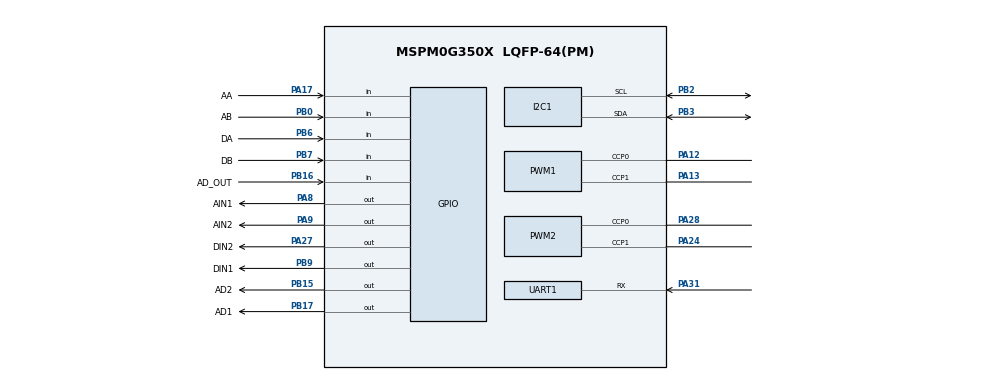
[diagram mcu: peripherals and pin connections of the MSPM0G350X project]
/**
 * @cliArgs --device "MSPM0G350X" --part "Default" --package "LQFP-64(PM)" --product "mspm0_sdk@2.10.00.04"
 * @versions {"tool":"1.26.2+4477"}
 */

/**
 * Import the modules used in this configuration.
 */
const GPIO    = scripting.addModule("/ti/driverlib/GPIO", {}, false);
const GPIO1   = GPIO.addInstance();
const GPIO2   = GPIO.addInstance();
const GPIO3   = GPIO.addInstance();
const GPIO4   = GPIO.addInstance();
const I2C     = scripting.addModule("/ti/driverlib/I2C", {}, false);
const I2C1    = I2C.addInstance();
const PWM     = scripting.addModule("/ti/driverlib/PWM", {}, false);
const PWM1    = PWM.addInstance();
const PWM2    = PWM.addInstance();
const SYSCTL  = scripting.addModule("/ti/driverlib/SYSCTL");
const SYSTICK = scripting.addModule("/ti/driverlib/SYSTICK");
const TIMER   = scripting.addModule("/ti/driverlib/TIMER", {}, false);
const TIMER1  = TIMER.addInstance();
const TIMER2  = TIMER.addInstance();
const UART    = scripting.addModule("/ti/driverlib/UART", {}, false);
const UART1   = UART.addInstance();

/**
 * Write custom configuration values to the imported modules.
 */
GPIO1.$name                         = "GPIO_MOTOR";
GPIO1.associatedPins.create(8);
GPIO1.associatedPins[0].$name       = "AIN1";
GPIO1.associatedPins[0].pin.$assign = "PA8";
GPIO1.associatedPins[1].$name       = "AIN2";
GPIO1.associatedPins[1].pin.$assign = "PA9";
GPIO1.associatedPins[2].$name       = "DIN1";
GPIO1.associatedPins[2].pin.$assign = "PB9";
GPIO1.associatedPins[3].$name       = "DIN2";
GPIO1.associatedPins[3].pin.$assign = "PA27";
GPIO1.associatedPins[4].$name       = "AA";
GPIO1.associatedPins[4].direction   = "INPUT";
GPIO1.associatedPins[4].interruptEn = true;
GPIO1.associatedPins[4].polarity    = "RISE";
GPIO1.associatedPins[4].pin.$assign = "PA17";
GPIO1.associatedPins[5].$name       = "AB";
GPIO1.associatedPins[5].direction   = "INPUT";
GPIO1.associatedPins[5].pin.$assign = "PB0";
GPIO1.associatedPins[6].$name       = "DA";
GPIO1.associatedPins[6].direction   = "INPUT";
GPIO1.associatedPins[6].interruptEn = true;
GPIO1.associatedPins[6].polarity    = "RISE";
GPIO1.associatedPins[6].pin.$assign = "PB6";
GPIO1.associatedPins[7].$name       = "DB";
GPIO1.associatedPins[7].direction   = "INPUT";
GPIO1.associatedPins[7].pin.$assign = "PB7";

const Board = scripting.addModule("/ti/driverlib/Board", {}, false);

GPIO2.$name                         = "TRACT";
GPIO2.associatedPins.create(4);
GPIO2.associatedPins[0].$name       = "AD0";
GPIO2.associatedPins[1].$name       = "AD1";
GPIO2.associatedPins[1].pin.$assign = "PB17";
GPIO2.associatedPins[2].$name       = "AD2";
GPIO2.associatedPins[2].pin.$assign = "PB15";
GPIO2.associatedPins[3].$name       = "AD_OUT";
GPIO2.associatedPins[3].direction   = "INPUT";
GPIO2.associatedPins[3].pin.$assign = "PB16";

GPIO3.$name                              = "USER_SWITCHES_PA18";
GPIO3.associatedPins[0].direction        = "INPUT";
GPIO3.associatedPins[0].internalResistor = "PULL_UP";
GPIO3.associatedPins[0].assignedPort     = "PORTA";
GPIO3.associatedPins[0].assignedPin      = "18";
GPIO3.associatedPins[0].$name            = "USER_SWITCH_PA18";

GPIO4.$name                          = "GPIO_SWITCHES_PB21";
GPIO4.associatedPins[0].direction    = "INPUT";
GPIO4.associatedPins[0].$name        = "USER_SWITCH_1";
GPIO4.associatedPins[0].assignedPort = "PORTB";
GPIO4.associatedPins[0].assignedPin  = "21";

I2C1.$name                             = "OLED";
I2C1.basicEnableController             = true;
I2C1.basicControllerStandardBusSpeed   = "Fast";
I2C1.peripheral.sdaPin.$assign         = "PB3";
I2C1.peripheral.sclPin.$assign         = "PB2";
I2C1.sdaPinConfig.hideOutputInversion  = scripting.forceWrite(false);
I2C1.sdaPinConfig.onlyInternalResistor = scripting.forceWrite(false);
I2C1.sdaPinConfig.passedPeripheralType = scripting.forceWrite("Digital");
I2C1.sdaPinConfig.$name                = "ti_driverlib_gpio_GPIOPinGeneric2";
I2C1.sdaPinConfig.enableConfig         = true;
I2C1.sdaPinConfig.internalResistor     = "PULL_UP";
I2C1.sclPinConfig.hideOutputInversion  = scripting.forceWrite(false);
I2C1.sclPinConfig.onlyInternalResistor = scripting.forceWrite(false);
I2C1.sclPinConfig.passedPeripheralType = scripting.forceWrite("Digital");
I2C1.sclPinConfig.$name                = "ti_driverlib_gpio_GPIOPinGeneric3";
I2C1.sclPinConfig.enableConfig         = true;
I2C1.sclPinConfig.internalResistor     = "PULL_UP";

PWM1.$name                              = "PWMA";
PWM1.timerCount                         = 3200;
PWM1.timerStartTimer                    = true;
PWM1.pwmMode                            = "EDGE_ALIGN_UP";
PWM1.peripheral.ccp0Pin.$assign         = "PA12";
PWM1.peripheral.ccp1Pin.$assign         = "PA13";
PWM1.PWM_CHANNEL_0.$name                = "ti_driverlib_pwm_PWMTimerCC0";
PWM1.PWM_CHANNEL_1.$name                = "ti_driverlib_pwm_PWMTimerCC1";
PWM1.ccp0PinConfig.direction            = scripting.forceWrite("OUTPUT");
PWM1.ccp0PinConfig.hideOutputInversion  = scripting.forceWrite(false);
PWM1.ccp0PinConfig.onlyInternalResistor = scripting.forceWrite(false);
PWM1.ccp0PinConfig.passedPeripheralType = scripting.forceWrite("Digital");
PWM1.ccp0PinConfig.$name                = "ti_driverlib_gpio_GPIOPinGeneric0";
PWM1.ccp1PinConfig.direction            = scripting.forceWrite("OUTPUT");
PWM1.ccp1PinConfig.hideOutputInversion  = scripting.forceWrite(false);
PWM1.ccp1PinConfig.onlyInternalResistor = scripting.forceWrite(false);
PWM1.ccp1PinConfig.passedPeripheralType = scripting.forceWrite("Digital");
PWM1.ccp1PinConfig.$name                = "ti_driverlib_gpio_GPIOPinGeneric1";

PWM2.$name                              = "PWM_0";
PWM2.clockPrescale                      = 32;
PWM2.timerCount                         = 19999;
PWM2.peripheral.ccp0Pin.$assign         = "PA28";
PWM2.peripheral.ccp1Pin.$assign         = "PA24";
PWM2.PWM_CHANNEL_0.$name                = "ti_driverlib_pwm_PWMTimerCC2";
PWM2.PWM_CHANNEL_0.ccValue              = 18499;
PWM2.PWM_CHANNEL_1.$name                = "ti_driverlib_pwm_PWMTimerCC3";
PWM2.PWM_CHANNEL_1.ccValue              = 18499;
PWM2.ccp0PinConfig.direction            = scripting.forceWrite("OUTPUT");
PWM2.ccp0PinConfig.hideOutputInversion  = scripting.forceWrite(false);
PWM2.ccp0PinConfig.onlyInternalResistor = scripting.forceWrite(false);
PWM2.ccp0PinConfig.passedPeripheralType = scripting.forceWrite("Digital");
PWM2.ccp0PinConfig.$name                = "ti_driverlib_gpio_GPIOPinGeneric6";
PWM2.ccp1PinConfig.direction            = scripting.forceWrite("OUTPUT");
PWM2.ccp1PinConfig.hideOutputInversion  = scripting.forceWrite(false);
PWM2.ccp1PinConfig.onlyInternalResistor = scripting.forceWrite(false);
PWM2.ccp1PinConfig.passedPeripheralType = scripting.forceWrite("Digital");
PWM2.ccp1PinConfig.$name                = "ti_driverlib_gpio_GPIOPinGeneric7";

SYSCTL.forceDefaultClkConfig = true;

SYSTICK.periodEnable    = true;
SYSTICK.interruptEnable = true;
SYSTICK.systickEnable   = true;
SYSTICK.period          = 32000;

TIMER1.$name            = "MOTOR_PID";
TIMER1.timerStartTimer  = true;
TIMER1.timerMode        = "PERIODIC_UP";
TIMER1.timerClkPrescale = 100;
TIMER1.timerPeriod      = "50ms";
TIMER1.interrupts       = ["LOAD"];

TIMER2.$name            = "interrupt";
TIMER2.timerClkPrescale = 100;
TIMER2.timerPeriod      = "10ms";
TIMER2.timerMode        = "PERIODIC_UP";
TIMER2.timerStartTimer  = true;
TIMER2.interrupts       = ["LOAD"];

UART1.$name                    = "UART_0";
UART1.targetBaudRate           = 115200;
UART1.enableFIFO               = true;
UART1.rxFifoThreshold          = "DL_UART_RX_FIFO_LEVEL_ONE_ENTRY";
UART1.enabledInterrupts        = ["RX"];
UART1.peripheral.rxPin.$assign = "PA31";
UART1.txPinConfig.$name        = "ti_driverlib_gpio_GPIOPinGeneric4";
UART1.rxPinConfig.$name        = "ti_driverlib_gpio_GPIOPinGeneric5";

/**
 * Pinmux solution for unlocked pins/peripherals. This ensures that minor changes to the automatic solver in a future
 * version of the tool will not impact the pinmux you originally saw.  These lines can be completely deleted in order to
 * re-solve from scratch.
 */
Board.peripheral.$suggestSolution            = "DEBUGSS";
Board.peripheral.swclkPin.$suggestSolution   = "PA20";
Board.peripheral.swdioPin.$suggestSolution   = "PA19";
GPIO2.associatedPins[0].pin.$suggestSolution = "PB13";
GPIO3.associatedPins[0].pin.$suggestSolution = "PA18";
GPIO4.associatedPins[0].pin.$suggestSolution = "PB21";
I2C1.peripheral.$suggestSolution             = "I2C1";
PWM1.peripheral.$suggestSolution             = "TIMG0";
PWM2.peripheral.$suggestSolution             = "TIMG7";
SYSCTL.peripheral.$suggestSolution           = "SYSCTL";
TIMER1.peripheral.$suggestSolution           = "TIMA1";
TIMER2.peripheral.$suggestSolution           = "TIMA0";
UART1.peripheral.$suggestSolution            = "UART0";
UART1.peripheral.txPin.$suggestSolution      = "PA0";
